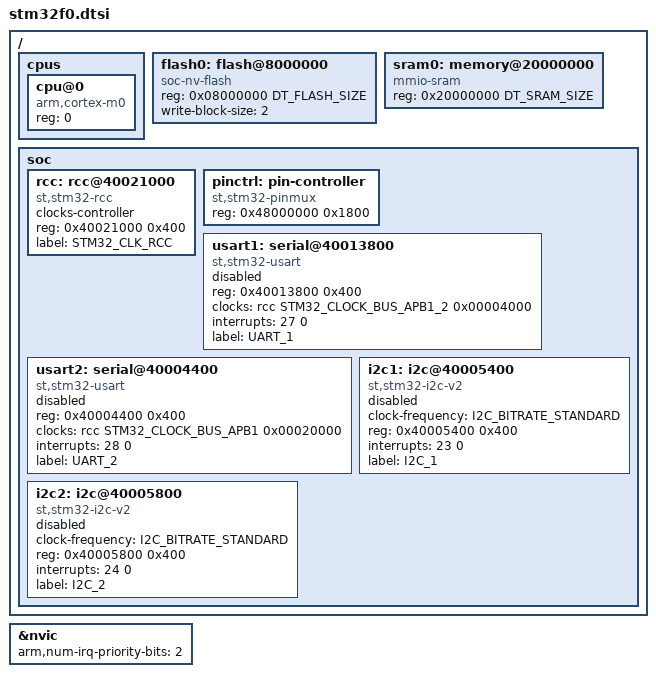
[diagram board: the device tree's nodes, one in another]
/*
 * Copyright (c) 2017 RnDity Sp. z o.o.
 *
 * SPDX-License-Identifier: Apache-2.0
 */

#include <st/stm32f0-pinctrl.dtsi>
#include <arm/armv6-m.dtsi>
#include <st/mem.h>
#include <dt-bindings/clock/stm32_clock.h>
#include <dt-bindings/i2c/i2c.h>

/ {
	cpus {
		#address-cells = <1>;
		#size-cells = <0>;

		cpu@0 {
			device_type = "cpu";
			compatible = "arm,cortex-m0";
			reg = <0>;
		};
	};

	flash0: flash@8000000 {
		compatible = "soc-nv-flash";
		reg = <0x08000000 DT_FLASH_SIZE>;

		write-block-size = <2>;
	};

	sram0: memory@20000000 {
		device_type = "memory";
		compatible = "mmio-sram";
		reg = <0x20000000 DT_SRAM_SIZE>;
	};

	soc {
		rcc: rcc@40021000 {
			compatible = "st,stm32-rcc";
			clocks-controller;
			#clocks-cells = <2>;
			reg = <0x40021000 0x400>;
			label = "STM32_CLK_RCC";
		};

		pinctrl: pin-controller {
			compatible = "st,stm32-pinmux";
			#address-cells = <1>;
			#size-cells = <1>;
			reg = <0x48000000 0x1800>;
		};

		usart1: serial@40013800 {
			compatible = "st,stm32-usart", "st,stm32-uart";
			reg = <0x40013800 0x400>;
			clocks = <&rcc STM32_CLOCK_BUS_APB1_2 0x00004000>;
			interrupts = <27 0>;
			status = "disabled";
			label = "UART_1";
		};

		usart2: serial@40004400 {
			compatible = "st,stm32-usart", "st,stm32-uart";
			reg = <0x40004400 0x400>;
			clocks = <&rcc STM32_CLOCK_BUS_APB1 0x00020000>;
			interrupts = <28 0>;
			status = "disabled";
			label = "UART_2";
		};

		i2c1: i2c@40005400 {
			compatible = "st,stm32-i2c-v2";
			clock-frequency = <I2C_BITRATE_STANDARD>;
			#address-cells = <1>;
			#size-cells = <0>;
			reg = <0x40005400 0x400>;
			interrupts = <23 0>;
			interrupt-names = "combined";
			status = "disabled";
			label= "I2C_1";
		};

		i2c2: i2c@40005800 {
			compatible = "st,stm32-i2c-v2";
			clock-frequency = <I2C_BITRATE_STANDARD>;
			#address-cells = <1>;
			#size-cells = <0>;
			reg = <0x40005800 0x400>;
			interrupts = <24 0>;
			interrupt-names = "combined";
			status = "disabled";
			label= "I2C_2";
		};
	};
};

&nvic {
	arm,num-irq-priority-bits = <2>;
};
